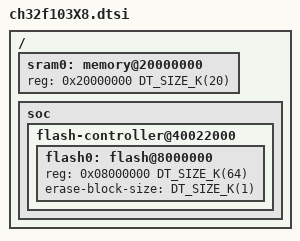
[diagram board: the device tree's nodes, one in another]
/*
 * Copyright (c) 2018 Linaro Limited
 *
 * SPDX-License-Identifier: Apache-2.0
 */

#include <mem.h>
#include <wch/ch32/ch32f.dtsi>

/ {
	sram0: memory@20000000 {
		reg = <0x20000000 DT_SIZE_K(20)>;
	};

	soc {

		flash-controller@40022000 {
			flash0: flash@8000000 {
				reg = <0x08000000 DT_SIZE_K(64)>;
				erase-block-size = <DT_SIZE_K(1)>;
			};
		};

	};

};
